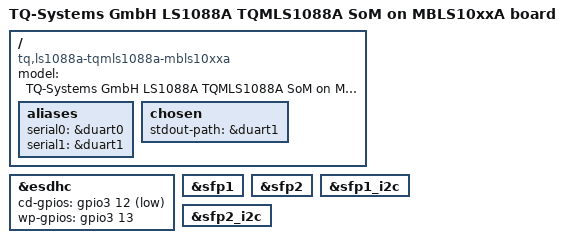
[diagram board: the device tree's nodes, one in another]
// SPDX-License-Identifier: (GPL-2.0-or-later OR MIT)
/*
 * Copyright (c) 2018-2023 TQ-Systems GmbH <linux@ew.tq-group.com>,
 * D-82229 Seefeld, Germany.
 * Author: Gregor Herburger, Timo Herbrecher
 *
 */

/dts-v1/;

#include <dt-bindings/gpio/gpio.h>

#include "fsl-ls1088a-tqmls1088a.dtsi"
#include "tqmls10xxa-mbls10xxa.dtsi"

/ {
	model = "TQ-Systems GmbH LS1088A TQMLS1088A SoM on MBLS10xxA board";
	compatible = "tq,ls1088a-tqmls1088a-mbls10xxa", "tq,ls1088a-tqmls1088a",
		     "fsl,ls1088a";

	aliases {
		serial0 = &duart0;
		serial1 = &duart1;
	};

	chosen {
		stdout-path = &duart1;
	};
};

&esdhc {
	cd-gpios = <&gpio3 12 GPIO_ACTIVE_LOW>;
	wp-gpios = <&gpio3 13 GPIO_ACTIVE_HIGH>;
};

&sfp1 {
	status = "okay";
};

&sfp2 {
	status = "okay";
};

&sfp1_i2c {
	status = "okay";
};

&sfp2_i2c {
	status = "okay";
};

#include "tqmls1088a-mbls10xxa-mc.dtsi"
